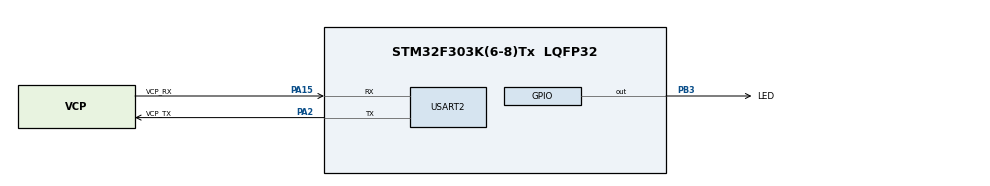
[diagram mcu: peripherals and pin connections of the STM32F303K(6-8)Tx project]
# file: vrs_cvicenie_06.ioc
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Mcu.Family=STM32F3
Mcu.Name=STM32F303K(6-8)Tx
Mcu.Package=LQFP32
NVIC.PriorityGroup=NVIC_PRIORITYGROUP_4
NVIC.USART2_IRQn=true\:0\:0\:false\:false\:true\:true\:true
PA13.GPIO_Label=SWDIO
PA13.Signal=SYS_JTMS-SWDIO
PA14.GPIO_Label=SWCLK
PA14.Signal=SYS_JTCK-SWCLK
PA15.GPIO_Label=VCP_RX
PA15.Mode=Asynchronous
PA15.Signal=USART2_RX
PA2.GPIO_Label=VCP_TX
PA2.Mode=Asynchronous
PA2.Signal=USART2_TX
PB3.GPIO_Label=LED
PB3.Signal=GPIO_Output
PF0\ /\ OSC_IN.GPIO_Label=MCO
PF0\ /\ OSC_IN.Signal=RCC_OSC_IN
ProjectManager.HeapSize=0x200
ProjectManager.StackSize=0x400
ProjectManager.TargetToolchain=STM32CubeIDE
RCC.AHBFreq_Value=20000000
RCC.APB1Freq_Value=20000000
RCC.APB1TimFreq_Value=20000000
RCC.APB2Freq_Value=20000000
RCC.APB2TimFreq_Value=20000000
RCC.CortexFreq_Value=20000000
RCC.HCLKFreq_Value=20000000
RCC.HSE_VALUE=8000000
RCC.HSI_VALUE=8000000
RCC.PLLMUL=RCC_PLL_MUL5
RCC.SYSCLKFreq_VALUE=20000000
RCC.SYSCLKSourceVirtual=RCC_SYSCLKSOURCE_PLLCLK
USART2.VirtualMode-Asynchronous=VM_ASYNC
board=NUCLEO-F303K8

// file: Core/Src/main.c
/* USER CODE BEGIN Header */
/**
 ******************************************************************************
 * @file           : main.c
 * @brief          : Main program body
 ******************************************************************************
 * @attention
 *
 * <h2><center>&copy; Copyright (c) 2021 STMicroelectronics.
 * All rights reserved.</center></h2>
 *
 * This software component is licensed by ST under BSD 3-Clause license,
 * the "License"; You may not use this file except in compliance with the
 * License. You may obtain a copy of the License at:
 *                        opensource.org/licenses/BSD-3-Clause
 *
 ******************************************************************************
 */
/* USER CODE END Header */
#include "main.h"
#include "usart.h"
#include "gpio.h"

/* USER CODE BEGIN Includes */
#include <string.h>
/* USER CODE END Includes */

/* USER CODE BEGIN PV */
uint8_t ledState = 0;
extern RX_UART_DATA RXDataIndexer;
extern uint8_t USART2_TX_IsEmpty;

/* USER CODE END PV */

void SystemClock_Config(void);

int main(void) {
	/* USER CODE BEGIN 1 */
	RXDataIndexer = RX_UART_DATA_None;
	/* USER CODE END 1 */

	/* MCU Configuration--------------------------------------------------------*/

	/* Reset of all peripherals, Initializes the Flash interface and the Systick. */

	LL_APB2_GRP1_EnableClock(LL_APB2_GRP1_PERIPH_SYSCFG);
	LL_APB1_GRP1_EnableClock(LL_APB1_GRP1_PERIPH_PWR);

	NVIC_SetPriorityGrouping(NVIC_PRIORITYGROUP_4);

	/* System interrupt init*/

	/* Configure the system clock */
	SystemClock_Config();

	/* Initialize all configured peripherals */
	MX_GPIO_Init();
	MX_USART2_UART_Init();
	/* USER CODE BEGIN 2 */
	USART2_RegisterCallback(USART_ProcessRxData);
	/* USER CODE END 2 */

	/* Infinite loop */
	while (1) {
		/* USER CODE BEGIN 3 */
		if (ledState == 1) {
			USART2_TransmitData(USART2, (uint8_t*) LED_ON_STR, LED_ON_STR_LEN);
		} else {
			USART2_TransmitData(USART2, (uint8_t*) LED_OFF_STR,
					LED_OFF_STR_LEN);
		}
		LL_mDelay(5000);
	}

	/* USER CODE END 3 */
}

void SystemClock_Config(void) {
	LL_FLASH_SetLatency(LL_FLASH_LATENCY_0);
	while (LL_FLASH_GetLatency() != LL_FLASH_LATENCY_0) {
	}
	LL_RCC_HSI_Enable();

	/* Wait till HSI is ready */
	while (LL_RCC_HSI_IsReady() != 1) {

	}
	LL_RCC_HSI_SetCalibTrimming(16);
	LL_RCC_PLL_ConfigDomain_SYS(LL_RCC_PLLSOURCE_HSI_DIV_2, LL_RCC_PLL_MUL_5);
	LL_RCC_PLL_Enable();

	/* Wait till PLL is ready */
	while (LL_RCC_PLL_IsReady() != 1) {

	}
	LL_RCC_SetAHBPrescaler(LL_RCC_SYSCLK_DIV_1);
	LL_RCC_SetAPB1Prescaler(LL_RCC_APB1_DIV_1);
	LL_RCC_SetAPB2Prescaler(LL_RCC_APB2_DIV_1);
	LL_RCC_SetSysClkSource(LL_RCC_SYS_CLKSOURCE_PLL);

	/* Wait till System clock is ready */
	while (LL_RCC_GetSysClkSource() != LL_RCC_SYS_CLKSOURCE_STATUS_PLL) {

	}
	LL_Init1msTick(20000000);
	LL_SetSystemCoreClock(20000000);
}

/* USER CODE BEGIN 4 */
void USART_ProcessRxData(uint8_t chr) {
	switch (RXDataIndexer) {
	default:
		if (chr == 'l')
			RXDataIndexer = RX_UART_DATA_l;
		break;
	case RX_UART_DATA_l:
		if (chr == 'e')
			RXDataIndexer = RX_UART_DATA_le;
		else if (chr != ENTER)
			RXDataIndexer = RX_UART_DATA_None;
		break;
	case RX_UART_DATA_le:
		if (chr == 'd')
			RXDataIndexer = RX_UART_DATA_led;
		else if (chr != ENTER)
			RXDataIndexer = RX_UART_DATA_None;
		break;
	case RX_UART_DATA_led:
		if (chr == 'O')
			RXDataIndexer = RX_UART_DATA_ledO;
		else if (chr != ENTER)
			RXDataIndexer = RX_UART_DATA_None;
		break;
	case RX_UART_DATA_ledO:
		if (chr == 'N')
			RXDataIndexer = RX_UART_DATA_ledON;
		else if (chr == 'F')
			RXDataIndexer = RX_UART_DATA_ledOF;
		else if (chr != ENTER)
			RXDataIndexer = RX_UART_DATA_None;
		break;
	case RX_UART_DATA_ledON:
		LL_GPIO_SetOutputPin(LED_GPIO_Port, LED_Pin);
		ledState = 1;
		RXDataIndexer = RX_UART_DATA_None;
		break;
	case RX_UART_DATA_ledOF:
		if (chr == 'F')
			RXDataIndexer = RX_UART_DATA_ledOFF;
		else if (chr != ENTER)
			RXDataIndexer = RX_UART_DATA_None;
		break;
	case RX_UART_DATA_ledOFF:
		LL_GPIO_ResetOutputPin(LED_GPIO_Port, LED_Pin);
		RXDataIndexer = RX_UART_DATA_None;
		ledState = 0;
		break;

	}
}
void USART2_TransmitData(USART_TypeDef *USARTx, uint8_t ptr[], uint16_t lenght) {
	if (ptr != NULL) {
		for (uint16_t i = 0; i < lenght; i++) {
			LL_USART_TransmitData8(USARTx, ptr[i]);
			LL_mDelay(5);
		}
	}
}
/* USER CODE END 4 */

void Error_Handler(void) {
	__disable_irq();
	while (1) {
	}
}

/************************ (C) COPYRIGHT STMicroelectronics *****END OF FILE****/
